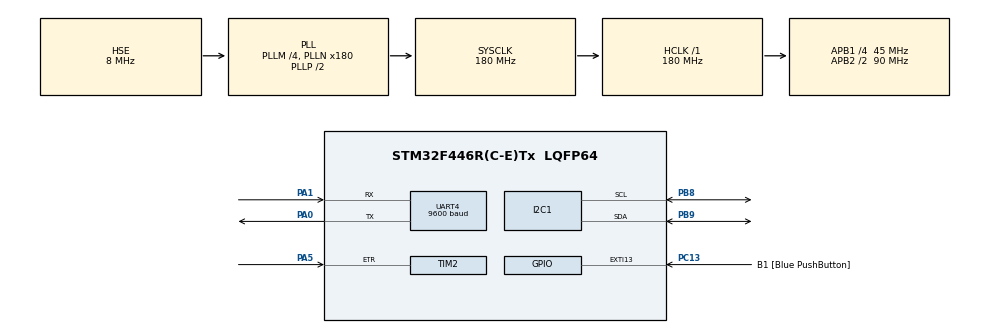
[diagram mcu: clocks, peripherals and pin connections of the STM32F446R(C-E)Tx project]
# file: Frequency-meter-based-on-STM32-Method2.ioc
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Mcu.Family=STM32F4
Mcu.Name=STM32F446R(C-E)Tx
Mcu.Package=LQFP64
NVIC.PriorityGroup=NVIC_PRIORITYGROUP_0
NVIC.TIM1_CC_IRQn=true\:0\:0\:false\:false\:true\:true\:true\:true
NVIC.TIM1_UP_TIM10_IRQn=true\:0\:0\:false\:false\:true\:true\:true\:true
NVIC.TIM2_IRQn=true\:0\:0\:false\:false\:true\:true\:true\:true
PA0-WKUP.GPIO_PuPd=GPIO_PULLDOWN
PA0-WKUP.Mode=Asynchronous
PA0-WKUP.Signal=UART4_TX
PA1.GPIO_PuPd=GPIO_PULLDOWN
PA1.Mode=Asynchronous
PA1.Signal=UART4_RX
PA13.GPIO_Label=TMS
PA13.Mode=Serial_Wire
PA13.Signal=SYS_JTMS-SWDIO
PA14.GPIO_Label=TCK
PA14.Mode=Serial_Wire
PA14.Signal=SYS_JTCK-SWCLK
PA5.GPIO_Speed=GPIO_SPEED_FREQ_VERY_HIGH
PA5.Signal=S_TIM2_CH1_ETR
PB3.GPIO_Label=SWO
PB3.Signal=SYS_JTDO-SWO
PB8.Mode=I2C
PB8.Signal=I2C1_SCL
PB9.Mode=I2C
PB9.Signal=I2C1_SDA
PC13.GPIO_Label=B1 [Blue PushButton]
PC13.GPIO_ModeDefaultEXTI=GPIO_MODE_IT_FALLING
PC13.Signal=GPXTI13
PC14-OSC32_IN.Mode=LSE-External-Oscillator
PC14-OSC32_IN.Signal=RCC_OSC32_IN
PC15-OSC32_OUT.Mode=LSE-External-Oscillator
PC15-OSC32_OUT.Signal=RCC_OSC32_OUT
PH0-OSC_IN.Mode=HSE-External-Oscillator
PH0-OSC_IN.Signal=RCC_OSC_IN
PH1-OSC_OUT.Mode=HSE-External-Oscillator
PH1-OSC_OUT.Signal=RCC_OSC_OUT
ProjectManager.HeapSize=0x200
ProjectManager.StackSize=0x400
ProjectManager.TargetToolchain=STM32CubeIDE
RCC.48MHZClocksFreq_Value=84000000
RCC.AHBFreq_Value=180000000
RCC.APB1CLKDivider=RCC_HCLK_DIV4
RCC.APB1Freq_Value=45000000
RCC.APB1TimFreq_Value=90000000
RCC.APB2CLKDivider=RCC_HCLK_DIV2
RCC.APB2Freq_Value=90000000
RCC.APB2TimFreq_Value=180000000
RCC.CortexFreq_Value=180000000
RCC.FLatency-AdvancedSettings=FLASH_LATENCY_5
RCC.HCLKFreq_Value=180000000
RCC.HSE_VALUE=8000000
RCC.HSI_VALUE=16000000
RCC.PLLM=4
RCC.PLLN=180
RCC.PLLSourceVirtual=RCC_PLLSOURCE_HSE
RCC.SYSCLKFreq_VALUE=180000000
RCC.SYSCLKSource=RCC_SYSCLKSOURCE_PLLCLK
RCC.USBFreq_Value=180000000
RCC.VCOOutputFreq_Value=360000000
SH.S_TIM2_CH1_ETR.0=TIM2_ETR,ClockSourceETR_Mode2
TIM1.AutoReloadPreload=TIM_AUTORELOAD_PRELOAD_ENABLE
TIM1.Channel-Output\ Compare1\ No\ Output=TIM_CHANNEL_1
TIM1.Period=10000-1
TIM1.Prescaler=18000-1
TIM1.Pulse-Output\ Compare1\ No\ Output=10000-3
TIM1.RepetitionCounter=0
TIM1.TIM_MasterOutputTrigger=TIM_TRGO_UPDATE
TIM1.TIM_MasterSlaveMode=TIM_MASTERSLAVEMODE_DISABLE
TIM2.AutoReloadPreload=TIM_AUTORELOAD_PRELOAD_ENABLE
TIM2.Period=4294967295
TIM2.Prescaler=0
TIM2.TIM_MasterOutputTrigger=TIM_TRGO_RESET
TIM2.TIM_MasterSlaveMode=TIM_MASTERSLAVEMODE_DISABLE
UART4.BaudRate=9600
UART4.Mode=MODE_TX
UART4.VirtualMode=Asynchronous
VP_TIM1_VS_ClockSourceINT.Mode=Internal
VP_TIM1_VS_no_output1.Mode=Output Compare1 No Output
VP_TIM2_VS_ClockSourceITR.Mode=TriggerSource_ITR0
VP_TIM2_VS_ControllerModeReset.Mode=Reset Mode
board=NUCLEO-F446RE

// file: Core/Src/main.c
/* USER CODE BEGIN Header */
/**
  ******************************************************************************
  * @file           : main.c
  * @brief          : Main program body
  ******************************************************************************
  * @attention
  *
  * Copyright (c) 2024 STMicroelectronics.
  * All rights reserved.
  *
  * This software is licensed under terms that can be found in the LICENSE file
  * in the root directory of this software component.
  * If no LICENSE file comes with this software, it is provided AS-IS.
  *
  ******************************************************************************
  */
/* USER CODE END Header */
#include "main.h"

/* USER CODE BEGIN Includes */
#include "liquidcrystal_i2c.h"
#include <string.h>
/* USER CODE END Includes */

I2C_HandleTypeDef hi2c1;

TIM_HandleTypeDef htim1;
TIM_HandleTypeDef htim2;

UART_HandleTypeDef huart4;

void SystemClock_Config(void);
static void MX_GPIO_Init(void);
static void MX_TIM1_Init(void);
static void MX_TIM2_Init(void);
static void MX_I2C1_Init(void);
static void MX_UART4_Init(void);

int main(void)
{

  /* MCU Configuration--------------------------------------------------------*/

  /* Reset of all peripherals, Initializes the Flash interface and the Systick. */
  HAL_Init();

  /* Configure the system clock */
  SystemClock_Config();

  /* Initialize all configured peripherals */
  MX_GPIO_Init();
  MX_TIM1_Init();
  MX_TIM2_Init();
  MX_I2C1_Init();
  MX_UART4_Init();
  /* USER CODE BEGIN 2 */
  HD44780_Init(2);
  HD44780_Clear();
  HAL_TIM_Base_Start(&htim2);
  HAL_TIM_OC_Start_IT(&htim1, TIM_CHANNEL_1);
  /* USER CODE END 2 */

  /* Infinite loop */
  while (1)
  {

  }
}

void SystemClock_Config(void)
{
  RCC_OscInitTypeDef RCC_OscInitStruct = {0};
  RCC_ClkInitTypeDef RCC_ClkInitStruct = {0};

  /** Configure the main internal regulator output voltage
  */
  __HAL_RCC_PWR_CLK_ENABLE();
  __HAL_PWR_VOLTAGESCALING_CONFIG(PWR_REGULATOR_VOLTAGE_SCALE1);

  /** Initializes the RCC Oscillators according to the specified parameters
  * in the RCC_OscInitTypeDef structure.
  */
  RCC_OscInitStruct.OscillatorType = RCC_OSCILLATORTYPE_HSE;
  RCC_OscInitStruct.HSEState = RCC_HSE_ON;
  RCC_OscInitStruct.PLL.PLLState = RCC_PLL_ON;
  RCC_OscInitStruct.PLL.PLLSource = RCC_PLLSOURCE_HSE;
  RCC_OscInitStruct.PLL.PLLM = 4;
  RCC_OscInitStruct.PLL.PLLN = 180;
  RCC_OscInitStruct.PLL.PLLP = RCC_PLLP_DIV2;
  RCC_OscInitStruct.PLL.PLLQ = 2;
  RCC_OscInitStruct.PLL.PLLR = 2;
  if (HAL_RCC_OscConfig(&RCC_OscInitStruct) != HAL_OK)
  {
    Error_Handler();
  }

  /** Activate the Over-Drive mode
  */
  if (HAL_PWREx_EnableOverDrive() != HAL_OK)
  {
    Error_Handler();
  }

  /** Initializes the CPU, AHB and APB buses clocks
  */
  RCC_ClkInitStruct.ClockType = RCC_CLOCKTYPE_HCLK|RCC_CLOCKTYPE_SYSCLK
                              |RCC_CLOCKTYPE_PCLK1|RCC_CLOCKTYPE_PCLK2;
  RCC_ClkInitStruct.SYSCLKSource = RCC_SYSCLKSOURCE_PLLCLK;
  RCC_ClkInitStruct.AHBCLKDivider = RCC_SYSCLK_DIV1;
  RCC_ClkInitStruct.APB1CLKDivider = RCC_HCLK_DIV4;
  RCC_ClkInitStruct.APB2CLKDivider = RCC_HCLK_DIV2;

  if (HAL_RCC_ClockConfig(&RCC_ClkInitStruct, FLASH_LATENCY_5) != HAL_OK)
  {
    Error_Handler();
  }
}

static void MX_I2C1_Init(void)
{

  hi2c1.Instance = I2C1;
  hi2c1.Init.ClockSpeed = 100000;
  hi2c1.Init.DutyCycle = I2C_DUTYCYCLE_2;
  hi2c1.Init.OwnAddress1 = 0;
  hi2c1.Init.AddressingMode = I2C_ADDRESSINGMODE_7BIT;
  hi2c1.Init.DualAddressMode = I2C_DUALADDRESS_DISABLE;
  hi2c1.Init.OwnAddress2 = 0;
  hi2c1.Init.GeneralCallMode = I2C_GENERALCALL_DISABLE;
  hi2c1.Init.NoStretchMode = I2C_NOSTRETCH_DISABLE;
  if (HAL_I2C_Init(&hi2c1) != HAL_OK)
  {
    Error_Handler();
  }

}

static void MX_TIM1_Init(void)
{

  TIM_ClockConfigTypeDef sClockSourceConfig = {0};
  TIM_MasterConfigTypeDef sMasterConfig = {0};
  TIM_OC_InitTypeDef sConfigOC = {0};
  TIM_BreakDeadTimeConfigTypeDef sBreakDeadTimeConfig = {0};

  htim1.Instance               = TIM1;
  htim1.Init.Prescaler         = PRESCALLER-1;
  htim1.Init.CounterMode       = TIM_COUNTERMODE_UP;
  htim1.Init.Period            = PERIOD+1;
  htim1.Init.ClockDivision     = TIM_CLOCKDIVISION_DIV1;
  htim1.Init.RepetitionCounter = 0;
  htim1.Init.AutoReloadPreload = TIM_AUTORELOAD_PRELOAD_ENABLE;
  if (HAL_TIM_Base_Init(&htim1) != HAL_OK)
  {
    Error_Handler();
  }
  sClockSourceConfig.ClockSource = TIM_CLOCKSOURCE_INTERNAL;
  if (HAL_TIM_ConfigClockSource(&htim1, &sClockSourceConfig) != HAL_OK)
  {
    Error_Handler();
  }
  if (HAL_TIM_OC_Init(&htim1) != HAL_OK)
  {
    Error_Handler();
  }
  sMasterConfig.MasterOutputTrigger = TIM_TRGO_UPDATE;
  sMasterConfig.MasterSlaveMode     = TIM_MASTERSLAVEMODE_DISABLE;
  if (HAL_TIMEx_MasterConfigSynchronization(&htim1, &sMasterConfig) != HAL_OK)
  {
    Error_Handler();
  }
  sConfigOC.OCMode       = TIM_OCMODE_TIMING;
  sConfigOC.Pulse        = CCR1-1;
  sConfigOC.OCPolarity   = TIM_OCPOLARITY_HIGH;
  sConfigOC.OCNPolarity  = TIM_OCNPOLARITY_HIGH;
  sConfigOC.OCFastMode   = TIM_OCFAST_DISABLE;
  sConfigOC.OCIdleState  = TIM_OCIDLESTATE_RESET;
  sConfigOC.OCNIdleState = TIM_OCNIDLESTATE_RESET;
  if (HAL_TIM_OC_ConfigChannel(&htim1, &sConfigOC, TIM_CHANNEL_1) != HAL_OK)
  {
    Error_Handler();
  }
  sBreakDeadTimeConfig.OffStateRunMode = TIM_OSSR_DISABLE;
  sBreakDeadTimeConfig.OffStateIDLEMode = TIM_OSSI_DISABLE;
  sBreakDeadTimeConfig.LockLevel = TIM_LOCKLEVEL_OFF;
  sBreakDeadTimeConfig.DeadTime = 0;
  sBreakDeadTimeConfig.BreakState = TIM_BREAK_DISABLE;
  sBreakDeadTimeConfig.BreakPolarity = TIM_BREAKPOLARITY_HIGH;
  sBreakDeadTimeConfig.AutomaticOutput = TIM_AUTOMATICOUTPUT_DISABLE;
  if (HAL_TIMEx_ConfigBreakDeadTime(&htim1, &sBreakDeadTimeConfig) != HAL_OK)
  {
    Error_Handler();
  }

}

static void MX_TIM2_Init(void)
{

  TIM_ClockConfigTypeDef sClockSourceConfig = {0};
  TIM_SlaveConfigTypeDef sSlaveConfig = {0};
  TIM_MasterConfigTypeDef sMasterConfig = {0};

  htim2.Instance               = TIM2;
  htim2.Init.Prescaler         = 0;
  htim2.Init.CounterMode       = TIM_COUNTERMODE_UP;
  htim2.Init.Period            = 4294967295;
  htim2.Init.ClockDivision     = TIM_CLOCKDIVISION_DIV1;
  htim2.Init.AutoReloadPreload = TIM_AUTORELOAD_PRELOAD_ENABLE;
  if (HAL_TIM_Base_Init(&htim2) != HAL_OK)
  {
    Error_Handler();
  }
  sClockSourceConfig.ClockSource    = TIM_CLOCKSOURCE_ETRMODE2;
  sClockSourceConfig.ClockPolarity  = TIM_CLOCKPOLARITY_NONINVERTED;
  sClockSourceConfig.ClockPrescaler = TIM_CLOCKPRESCALER_DIV1;
  sClockSourceConfig.ClockFilter    = 0;
  if (HAL_TIM_ConfigClockSource(&htim2, &sClockSourceConfig) != HAL_OK)
  {
    Error_Handler();
  }
  sSlaveConfig.SlaveMode = TIM_SLAVEMODE_RESET;
  sSlaveConfig.InputTrigger = TIM_TS_ITR0;
  if (HAL_TIM_SlaveConfigSynchro(&htim2, &sSlaveConfig) != HAL_OK)
  {
    Error_Handler();
  }
  sMasterConfig.MasterOutputTrigger = TIM_TRGO_RESET;
  sMasterConfig.MasterSlaveMode = TIM_MASTERSLAVEMODE_DISABLE;
  if (HAL_TIMEx_MasterConfigSynchronization(&htim2, &sMasterConfig) != HAL_OK)
  {
    Error_Handler();
  }

}

static void MX_UART4_Init(void)
{

  huart4.Instance = UART4;
  huart4.Init.BaudRate = 9600;
  huart4.Init.WordLength = UART_WORDLENGTH_8B;
  huart4.Init.StopBits = UART_STOPBITS_1;
  huart4.Init.Parity = UART_PARITY_NONE;
  huart4.Init.Mode = UART_MODE_TX;
  huart4.Init.HwFlowCtl = UART_HWCONTROL_NONE;
  huart4.Init.OverSampling = UART_OVERSAMPLING_16;
  if (HAL_UART_Init(&huart4) != HAL_OK)
  {
    Error_Handler();
  }

}

static void MX_GPIO_Init(void)
{
  GPIO_InitTypeDef GPIO_InitStruct = {0};

  /* GPIO Ports Clock Enable */
  __HAL_RCC_GPIOC_CLK_ENABLE();
  __HAL_RCC_GPIOH_CLK_ENABLE();
  __HAL_RCC_GPIOA_CLK_ENABLE();
  __HAL_RCC_GPIOB_CLK_ENABLE();

  /*Configure GPIO pin : B1_Pin */
  GPIO_InitStruct.Pin = B1_Pin;
  GPIO_InitStruct.Mode = GPIO_MODE_IT_FALLING;
  GPIO_InitStruct.Pull = GPIO_NOPULL;
  HAL_GPIO_Init(B1_GPIO_Port, &GPIO_InitStruct);

}

void Error_Handler(void)
{
  __disable_irq();
  while (1)
  {
  }
}
